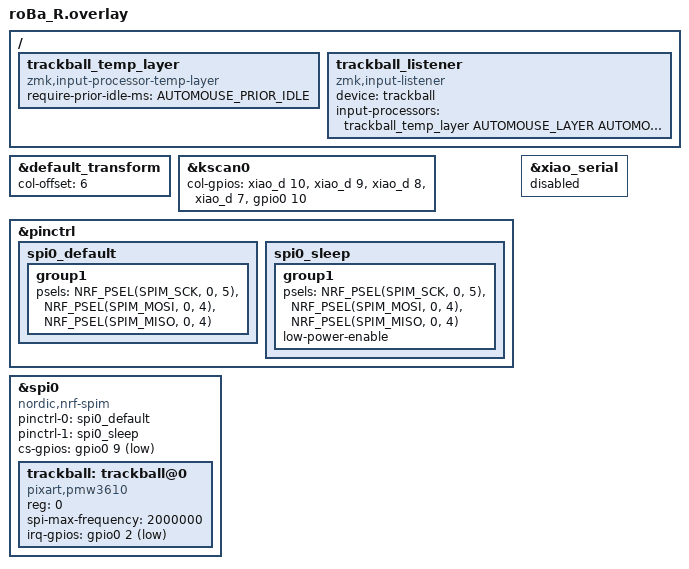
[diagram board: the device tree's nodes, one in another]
#include "roBa.dtsi"
#include <input/processors.dtsi>

#define AUTOMOUSE_LAYER 4
/*
 * 解除タイムアウトは400ms。以前の50msはスクロールのティック間隔(>50ms)で
 * レイヤー4が解除→再有効化とトグルし、layer_state_changedイベントの氾濫と
 * temp_layer_action_msgqの溢れ(-EAGAIN)→レイヤー固着(フリーズ)を招いていた。
 * 連続入力中に解除予約が延長され続ける値にして、トグルを起こさせない。
 */
#define AUTOMOUSE_TIMEOUT 400
#define AUTOMOUSE_PRIOR_IDLE 500

&default_transform {
    col-offset = <6>;
};

&kscan0 {
    col-gpios
        = <&xiao_d 10 GPIO_ACTIVE_HIGH>
        , <&xiao_d 9 GPIO_ACTIVE_HIGH>
        , <&xiao_d 8 GPIO_ACTIVE_HIGH>
        , <&xiao_d 7 GPIO_ACTIVE_HIGH>
        , <&gpio0 10 GPIO_ACTIVE_HIGH>
        ;
};

/ {
    trackball_temp_layer: trackball_temp_layer {
        compatible = "zmk,input-processor-temp-layer";
        #input-processor-cells = <2>;
        require-prior-idle-ms = <AUTOMOUSE_PRIOR_IDLE>;
    };

    trackball_listener: trackball_listener {
        compatible = "zmk,input-listener";
        status = "okay";

        device = <&trackball>;

        /*
         * automouseはこのtemp-layer入力プロセッサに一本化(ドライバ側は無効)。
         *
         * 最後のキー入力からAUTOMOUSE_PRIOR_IDLE(500)ミリ秒以上経過した状態で
         * トラックボールを動かすと、AUTOMOUSE_LAYER(4)を一時的に有効化する。
         * これによりタイプ中の誤マウス層化を防ぐ。
         *
         * 最後のトラックボール入力からAUTOMOUSE_TIMEOUT(400)ミリ秒で解除する。
         * 連続スクロール中はこの予約が延長され続けるため、レイヤー4のトグルは起きない。
         */
        input-processors = <
            &trackball_temp_layer
                AUTOMOUSE_LAYER
                AUTOMOUSE_TIMEOUT
        >;
    };
};

&pinctrl {
    spi0_default: spi0_default {
        group1 {
            psels = <NRF_PSEL(SPIM_SCK, 0, 5)>,
                <NRF_PSEL(SPIM_MOSI, 0, 4)>,
                <NRF_PSEL(SPIM_MISO, 0, 4)>;
        };
    };

    spi0_sleep: spi0_sleep {
        group1 {
            psels = <NRF_PSEL(SPIM_SCK, 0, 5)>,
                <NRF_PSEL(SPIM_MOSI, 0, 4)>,
                <NRF_PSEL(SPIM_MISO, 0, 4)>;
            low-power-enable;
        };
    };
};

&xiao_serial { status = "disabled"; };

&spi0 {
    status = "okay";
    compatible = "nordic,nrf-spim";
    pinctrl-0 = <&spi0_default>;
    pinctrl-1 = <&spi0_sleep>;
    pinctrl-names = "default", "sleep";
    cs-gpios = <&gpio0 9 GPIO_ACTIVE_LOW>;

    trackball: trackball@0 {
        status = "okay";
        compatible = "pixart,pmw3610";
        reg = <0>;
        spi-max-frequency = <2000000>;
        irq-gpios = <&gpio0 2 (GPIO_ACTIVE_LOW | GPIO_PULL_UP)>;
    };
};
